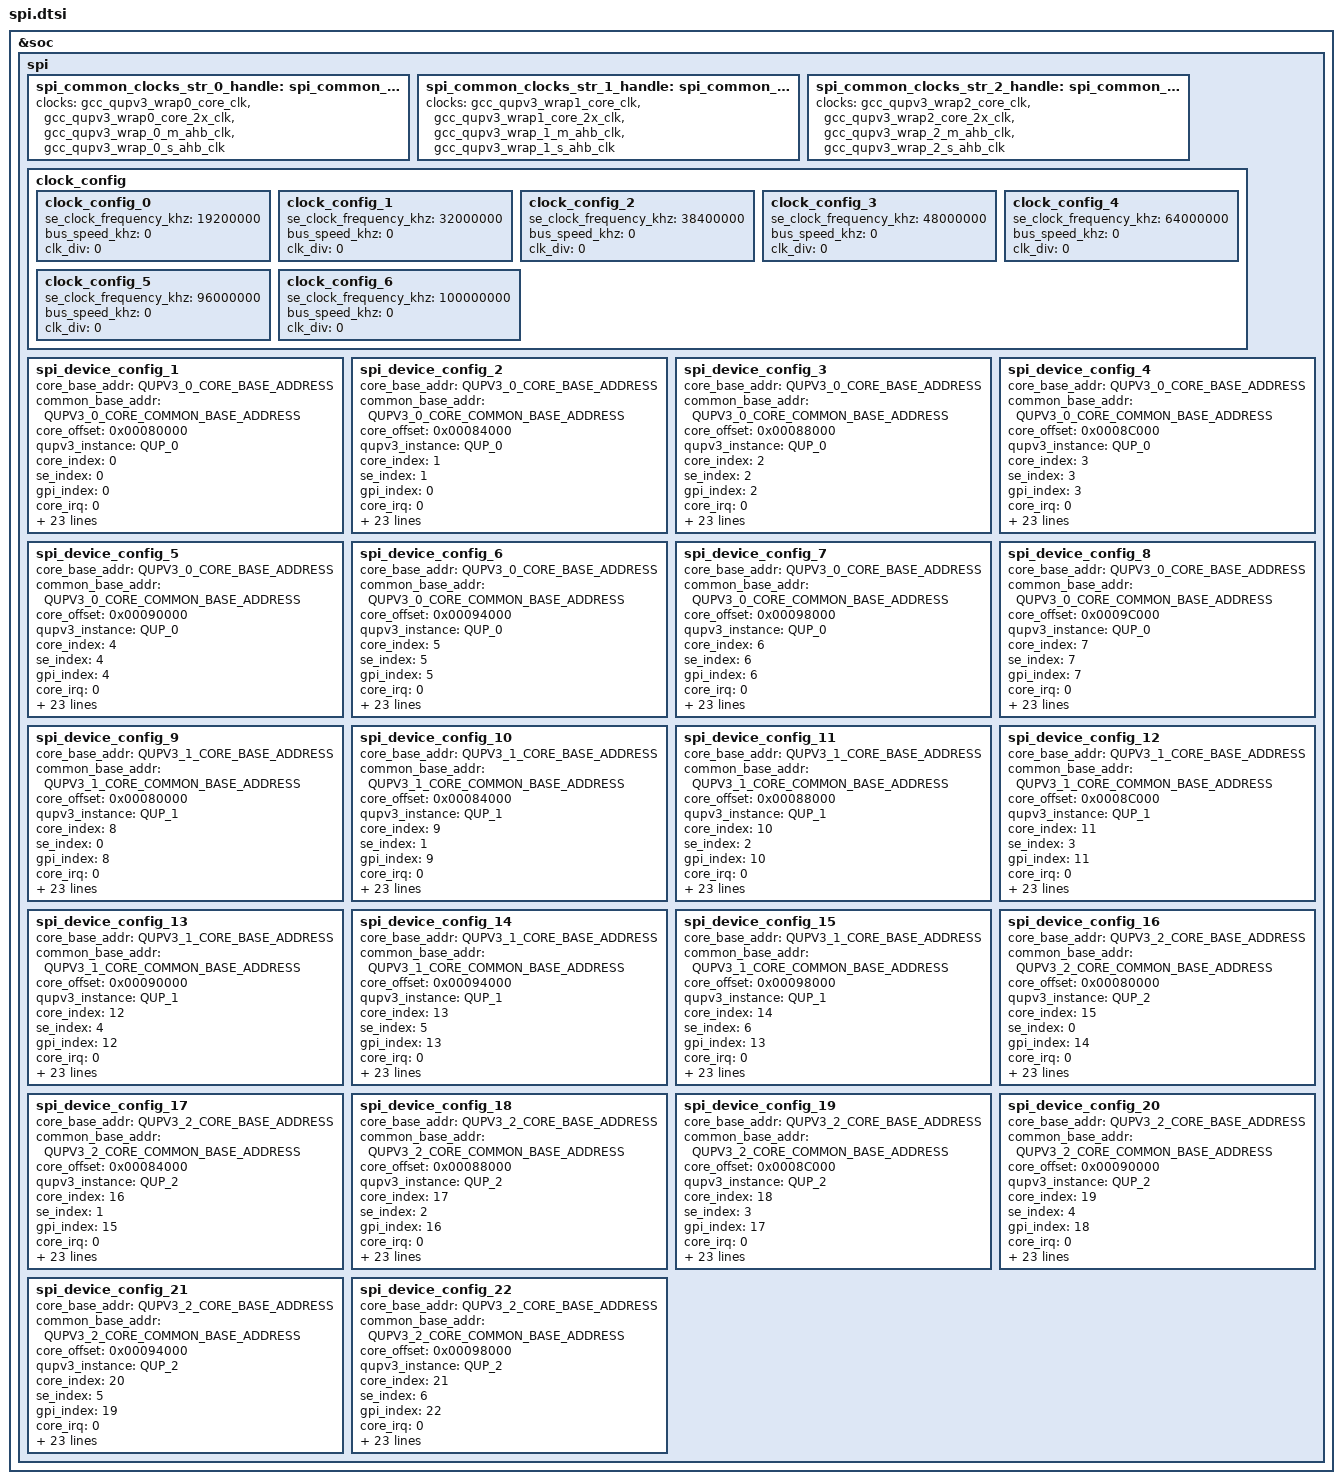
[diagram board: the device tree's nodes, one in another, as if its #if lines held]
/**

This is the settings file for spi

Copyright (c) 2021, 2023 Qualcomm Technologies, Inc.
All Rights Reserved.
Confidential and Proprietary - Qualcomm Technologies, Inc.
*/

#include <spi_defines.h>

&soc {
 spi {
  spi_common_clocks_str_0_handle:spi_common_clocks_str_0 {
    clocks = "gcc_qupv3_wrap0_core_clk", "gcc_qupv3_wrap0_core_2x_clk",
             "gcc_qupv3_wrap_0_m_ahb_clk", "gcc_qupv3_wrap_0_s_ahb_clk" ;
  };
  spi_common_clocks_str_1_handle:spi_common_clocks_str_1 {
    clocks = "gcc_qupv3_wrap1_core_clk", "gcc_qupv3_wrap1_core_2x_clk",
             "gcc_qupv3_wrap_1_m_ahb_clk", "gcc_qupv3_wrap_1_s_ahb_clk";
  };
  spi_common_clocks_str_2_handle:spi_common_clocks_str_2 {
    clocks = "gcc_qupv3_wrap2_core_clk", "gcc_qupv3_wrap2_core_2x_clk",
             "gcc_qupv3_wrap_2_m_ahb_clk", "gcc_qupv3_wrap_2_s_ahb_clk" ;
  };
  clock_config {
      clock_config_0 {
        se_clock_frequency_khz =<19200000>;
        bus_speed_khz = <0>;
        clk_div = /bits/ 8 <0>;
      };
      clock_config_1 {
          se_clock_frequency_khz =<32000000>;
          bus_speed_khz = <0>;
          clk_div = /bits/ 8 <0>;
      };
      clock_config_2 {
          se_clock_frequency_khz =<38400000>;
          bus_speed_khz = <0>;
          clk_div = /bits/ 8 <0>;
      };
      clock_config_3 {
          se_clock_frequency_khz =<48000000>;
          bus_speed_khz = <0>;
          clk_div = /bits/ 8 <0>;
      };
      clock_config_4 {
          se_clock_frequency_khz =<64000000>;
          bus_speed_khz = <0>;
          clk_div = /bits/ 8 <0>;
      };
      clock_config_5 {
          se_clock_frequency_khz =<96000000>;
          bus_speed_khz = <0>;
          clk_div = /bits/ 8 <0>;
      };
      clock_config_6 {
          se_clock_frequency_khz =<100000000>;
          bus_speed_khz = <0>;
          clk_div = /bits/ 8 <0>;
      };
    };
#ifdef SSC_USE_SPI_01
  spi_device_config_1 {
    core_base_addr              = <QUPV3_0_CORE_BASE_ADDRESS>;
    common_base_addr            = <QUPV3_0_CORE_COMMON_BASE_ADDRESS>;
    core_offset                 = <0x00080000>;
    qupv3_instance              = /bits/ 8 <QUP_0>;
    core_index                  = /bits/ 8 <0>;
    se_index                    = /bits/ 8 <0>;
    gpi_index                   = /bits/ 8 <0>;
    core_irq                    = <0>;
    polled_mode                 = <1>;
    min_data_length_for_dma     = <0>;
    
    miso_encoding                = <SPI_01_MISO>;
    mosi_encoding                = <SPI_01_MOSI>;
    clk_encoding                 = <SPI_01_CLK>;
    cs_encoding_0                = <SPI_01_CS_0>;
    cs_encoding_1                = <0>;
    cs_encoding_2                = <0>;
    cs_encoding_3                = <0>;
    sleep_miso_encoding          = <0>;
    sleep_mosi_encoding          = <0>;
    sleep_clk_encoding           = <0>;
    sleep_cs_encoding_0          = <0>;
	sleep_cs_encoding_1          = <0>;
	sleep_cs_encoding_2          = <0>;
	sleep_cs_encoding_3          = <0>;

    tcsr_reg_offset             = <0x00000000>;
    tcsr_base_addr              = <0x01FC0000>;
    tcsr_reg_value              = <0x00000000>;
    
    se_clock_frequency          = <19200>;
    se_clock_dfs_index          = /bits/ 8 <1>;

    common_clocks               = <&spi_common_clocks_str_0_handle>;
    se_clock                    = "gcc_qupv3_wrap0_s0_clk";
  };
#endif
#ifdef SSC_USE_SPI_02
  spi_device_config_2 {
    core_base_addr              = <QUPV3_0_CORE_BASE_ADDRESS>;
    common_base_addr            = <QUPV3_0_CORE_COMMON_BASE_ADDRESS>;
    core_offset                 = <0x00084000>;
    qupv3_instance              = /bits/ 8 <QUP_0>;
    core_index                  = /bits/ 8 <1>;
    se_index                    = /bits/ 8 <1>;
    gpi_index                   = /bits/ 8 <0>;
    core_irq                    = <0>;
    polled_mode                 = <1>;
    min_data_length_for_dma     = <0>;
    
    miso_encoding                = <SPI_02_MISO>;
    mosi_encoding                = <SPI_02_MOSI>;
    clk_encoding                 = <SPI_02_CLK>;
    cs_encoding_0                = <SPI_02_CS_0>;
	cs_encoding_1                = <0>;
    cs_encoding_2                = <0>;
    cs_encoding_3                = <0>;
    sleep_miso_encoding          = <0>;
    sleep_mosi_encoding          = <0>;
    sleep_clk_encoding           = <0>;
    sleep_cs_encoding_0          = <0>;
	sleep_cs_encoding_1          = <0>;
	sleep_cs_encoding_2          = <0>;
	sleep_cs_encoding_3          = <0>;

    tcsr_reg_offset             = <0x00000000>;
    tcsr_base_addr              = <0x01FC0000>;
    tcsr_reg_value              = <0x00000000>;
    
    se_clock_frequency          = <19200>;
    se_clock_dfs_index          = /bits/ 8 <1>;
    
    common_clocks               = <&spi_common_clocks_str_0_handle>;
    se_clock                    = "gcc_qupv3_wrap0_s1_clk";
  };
#endif
#ifdef SSC_USE_SPI_03
  spi_device_config_3 {
    core_base_addr              = <QUPV3_0_CORE_BASE_ADDRESS>;
    common_base_addr            = <QUPV3_0_CORE_COMMON_BASE_ADDRESS>;
    core_offset                 = <0x00088000>;
    qupv3_instance              = /bits/ 8 <QUP_0>;
    core_index                  = /bits/ 8 <2>;
    se_index                    = /bits/ 8 <2>;
    gpi_index                   = /bits/ 8 <2>;
    core_irq                    = <0>;
    polled_mode                 = <1>;
    min_data_length_for_dma     = <0>;
    
    
    miso_encoding                = <SPI_03_MISO>;
    mosi_encoding                = <SPI_03_MOSI>;
    clk_encoding                 = <SPI_03_CLK>;
    cs_encoding_0                = <SPI_03_CS_0>;
    cs_encoding_1                = <0>;
    cs_encoding_2                = <0>;
    cs_encoding_3                = <0>;
    sleep_miso_encoding          = <0>;
    sleep_mosi_encoding          = <0>;
    sleep_clk_encoding           = <0>;
    sleep_cs_encoding_0          = <0>;
	sleep_cs_encoding_1          = <0>;
	sleep_cs_encoding_2          = <0>;
	sleep_cs_encoding_3          = <0>;

    tcsr_reg_offset             = <0x00000000>;
    tcsr_base_addr              = <0x01FC0000>;    
    tcsr_reg_value              = <0x00000000>;
    
    se_clock_frequency          = <19200>;
    se_clock_dfs_index          = /bits/ 8 <1>;    

    common_clocks               = <&spi_common_clocks_str_0_handle>;
    se_clock                    = "gcc_qupv3_wrap0_s2_clk";

  };
#endif
#ifdef SSC_USE_SPI_04
  spi_device_config_4 {
    core_base_addr              = <QUPV3_0_CORE_BASE_ADDRESS>;
    common_base_addr            = <QUPV3_0_CORE_COMMON_BASE_ADDRESS>;
    core_offset                 = <0x0008C000>;
    qupv3_instance              = /bits/ 8 <QUP_0>;
    core_index                  = /bits/ 8 <3>;
    se_index                    = /bits/ 8 <3>;
    gpi_index                   = /bits/ 8 <3>;
    core_irq                    = <0>;
    polled_mode                 = <1>;
    min_data_length_for_dma     = <0>;
    
    
    miso_encoding                = <SPI_04_MISO>;
    mosi_encoding                = <SPI_04_MOSI>;
    clk_encoding                 = <SPI_04_CLK>;
    cs_encoding_0                = <SPI_04_CS_0>;
    cs_encoding_1                = <0>;
    cs_encoding_2                = <0>;
    cs_encoding_3                = <0>;
    sleep_miso_encoding          = <0>;
    sleep_mosi_encoding          = <0>;
    sleep_clk_encoding           = <0>;
    sleep_cs_encoding_0          = <0>;
	sleep_cs_encoding_1          = <0>;
	sleep_cs_encoding_2          = <0>;
	sleep_cs_encoding_3          = <0>;

    tcsr_reg_offset             = <0x00000000>;
    tcsr_base_addr              = <0x01FC0000>;    
    tcsr_reg_value              = <0x00000000>;
    
    se_clock_frequency          = <19200>;
    se_clock_dfs_index          = /bits/ 8 <1>;
    
    common_clocks               = <&spi_common_clocks_str_0_handle>;
    se_clock                    = "gcc_qupv3_wrap0_s3_clk";
  };
#endif
#ifdef SSC_USE_SPI_05
  spi_device_config_5 {
    core_base_addr              = <QUPV3_0_CORE_BASE_ADDRESS>;
    common_base_addr            = <QUPV3_0_CORE_COMMON_BASE_ADDRESS>;
    core_offset                 = <0x00090000>;
    qupv3_instance              = /bits/ 8 <QUP_0>;
    core_index                  = /bits/ 8 <4>;
    se_index                    = /bits/ 8 <4>;
    gpi_index                   = /bits/ 8 <4>;
    core_irq                    = <0>;
    polled_mode                 = <1>;
    min_data_length_for_dma     = <0>;
        
    miso_encoding                = <SPI_05_MISO>;
    mosi_encoding                = <SPI_05_MOSI>;
    clk_encoding                 = <SPI_05_CLK>;
    cs_encoding_0                = <SPI_05_CS_0>;
    cs_encoding_1                = <0>;
    cs_encoding_2                = <0>;
    cs_encoding_3                = <0>;
    sleep_miso_encoding          = <0>;
    sleep_mosi_encoding          = <0>;
    sleep_clk_encoding           = <0>;
    sleep_cs_encoding_0          = <0>;
	sleep_cs_encoding_1          = <0>;
	sleep_cs_encoding_2          = <0>;
	sleep_cs_encoding_3          = <0>;

    tcsr_reg_offset             = <0x00000000>;
    tcsr_base_addr              = <0x01FC0000>;    
    tcsr_reg_value              = <0x00000000>;
    
    se_clock_frequency          = <19200>;
    se_clock_dfs_index          = /bits/ 8 <1>;
    
    common_clocks               = <&spi_common_clocks_str_0_handle>;
    se_clock                    = "gcc_qupv3_wrap0_s4_clk";
	
  };
#endif
#ifdef SSC_USE_SPI_06
  spi_device_config_6 {
    core_base_addr              = <QUPV3_0_CORE_BASE_ADDRESS>;
    common_base_addr            = <QUPV3_0_CORE_COMMON_BASE_ADDRESS>;
    core_offset                 = <0x00094000>;
    qupv3_instance              = /bits/ 8 <QUP_0>;
    core_index                  = /bits/ 8 <5>;
    se_index                    = /bits/ 8 <5>;
    gpi_index                   = /bits/ 8 <5>;
    core_irq                    = <0>;
    polled_mode                 = <1>;
    min_data_length_for_dma     = <0>;
        
    miso_encoding               = <SPI_06_MISO>;
    mosi_encoding               = <SPI_06_MOSI>;
    clk_encoding                = <SPI_06_CLK>;
    cs_encoding_0               = <SPI_06_CS_0>;
    cs_encoding_1               = <0>;
    cs_encoding_2               = <0>;
    cs_encoding_3               = <0>;
    sleep_miso_encoding         = <0>;
    sleep_mosi_encoding         = <0>;
    sleep_clk_encoding          = <0>;
    sleep_cs_encoding_0         = <0>;
	sleep_cs_encoding_1         = <0>;
	sleep_cs_encoding_2         = <0>;
	sleep_cs_encoding_3         = <0>;

    tcsr_reg_offset             = <0x00000000>;
    tcsr_base_addr              = <0x01FC0000>;
    tcsr_reg_value              = <0x00000000>;
    
    se_clock_frequency          = <19200>;
    se_clock_dfs_index          = /bits/ 8 <1>;

    common_clocks               = <&spi_common_clocks_str_0_handle>;
    se_clock                    = "gcc_qupv3_wrap0_s5_clk";
	
  };
#endif
#ifdef SSC_USE_SPI_07
  spi_device_config_7 {
    core_base_addr              = <QUPV3_0_CORE_BASE_ADDRESS>;
    common_base_addr            = <QUPV3_0_CORE_COMMON_BASE_ADDRESS>;
    core_offset                 = <0x00098000>;
    qupv3_instance              = /bits/ 8 <QUP_0>;
    core_index                  = /bits/ 8 <6>;
    se_index                    = /bits/ 8 <6>;
    gpi_index                   = /bits/ 8 <6>;
    core_irq                    = <0>;
    polled_mode                 = <1>;
    min_data_length_for_dma     = <0>;
    
    
    miso_encoding               = <SPI_07_MISO>;
    mosi_encoding               = <SPI_07_MOSI>;
    clk_encoding                = <SPI_07_CLK>;
    cs_encoding_0               = <SPI_07_CS_0>;
    cs_encoding_1               = <0>;
    cs_encoding_2               = <0>;
    cs_encoding_3               = <0>;
    sleep_miso_encoding         = <0>;
    sleep_mosi_encoding         = <0>;
    sleep_clk_encoding          = <0>;
    sleep_cs_encoding_0         = <0>;
	sleep_cs_encoding_1         = <0>;
	sleep_cs_encoding_2         = <0>;
	sleep_cs_encoding_3         = <0>;

    tcsr_reg_offset             = <0x00000000>;
    tcsr_base_addr              = <0x01FC0000>;
    tcsr_reg_value              = <0x00000000>;
    
    se_clock_frequency          = <19200>;
    se_clock_dfs_index          = /bits/ 8 <1>;
    
    common_clocks               = <&spi_common_clocks_str_0_handle>;
    se_clock                    = "gcc_qupv3_wrap0_s6_clk";
	
  };
#endif
#ifdef SSC_USE_SPI_08
  spi_device_config_8 {
    core_base_addr              = <QUPV3_0_CORE_BASE_ADDRESS>;
    common_base_addr            = <QUPV3_0_CORE_COMMON_BASE_ADDRESS>;
    core_offset                 = <0x0009C000>;
    qupv3_instance              = /bits/ 8 <QUP_0>;
    core_index                  = /bits/ 8 <7>;
    se_index                    = /bits/ 8 <7>;
    gpi_index                   = /bits/ 8 <7>;
    core_irq                    = <0>;
    polled_mode                 = <1>;
    min_data_length_for_dma     = <0>;
    
    miso_encoding               = <SPI_08_MISO>;
    mosi_encoding               = <SPI_08_MOSI>;
    clk_encoding                = <SPI_08_CLK>;
    cs_encoding_0               = <SPI_08_CS_0>;
    cs_encoding_1               = <0>;
    cs_encoding_2               = <0>;
    cs_encoding_3               = <0>;
    sleep_miso_encoding         = <0>;
    sleep_mosi_encoding         = <0>;
    sleep_clk_encoding          = <0>;
    sleep_cs_encoding_0         = <0>;
	sleep_cs_encoding_1         = <0>;
	sleep_cs_encoding_2         = <0>;
	sleep_cs_encoding_3         = <0>;

    tcsr_reg_offset             = <0x00000000>;
    tcsr_base_addr              = <0x01FC0000>;
    tcsr_reg_value              = <0x00000000>;
    
    se_clock_frequency          = <19200>;
    se_clock_dfs_index          = /bits/ 8 <1>;    

    common_clocks               = <&spi_common_clocks_str_0_handle>;
    se_clock                    = "gcc_qupv3_wrap0_s7_clk";
  };
#endif
#ifdef SSC_USE_SPI_09
  spi_device_config_9 {
    core_base_addr              = <QUPV3_1_CORE_BASE_ADDRESS>;
    common_base_addr            = <QUPV3_1_CORE_COMMON_BASE_ADDRESS>;
    core_offset                 = <0x00080000>;
    qupv3_instance              = /bits/ 8 <QUP_1>;
    core_index                  = /bits/ 8 <8>;
    se_index                    = /bits/ 8 <0>;
    gpi_index                   = /bits/ 8 <8>;
    core_irq                    = <0>;
    polled_mode                 = <1>;
    min_data_length_for_dma     = <0>;
    
    miso_encoding               = <SPI_09_MISO>;
    mosi_encoding               = <SPI_09_MOSI>;
    clk_encoding                = <SPI_09_CLK>;
    cs_encoding_0               = <SPI_09_CS_0>;
    cs_encoding_1               = <0>;
    cs_encoding_2               = <0>;
    cs_encoding_3               = <0>;
    sleep_miso_encoding         = <0>;
    sleep_mosi_encoding         = <0>;
    sleep_clk_encoding          = <0>;
    sleep_cs_encoding_0         = <0>;
	sleep_cs_encoding_1         = <0>;
	sleep_cs_encoding_2         = <0>;
	sleep_cs_encoding_3         = <0>;

    tcsr_reg_offset             = <0x00000000>;
    tcsr_base_addr              = <0x01FC0000>;
    tcsr_reg_value              = <0x00000000>;

    se_clock_frequency          = <19200>;
    se_clock_dfs_index          = /bits/ 8 <1>;    
    
    common_clocks               = <&spi_common_clocks_str_1_handle>;
    se_clock                    = "gcc_qupv3_wrap1_s0_clk";
	
  };
#endif
#ifdef SSC_USE_SPI_10
  spi_device_config_10 {
    core_base_addr              = <QUPV3_1_CORE_BASE_ADDRESS>;
    common_base_addr            = <QUPV3_1_CORE_COMMON_BASE_ADDRESS>;
    core_offset                 = <0x00084000>;
    qupv3_instance              = /bits/ 8 <QUP_1>;
    core_index                  = /bits/ 8 <9>;
    se_index                    = /bits/ 8 <1>;
    gpi_index                   = /bits/ 8 <9>;
    core_irq                    = <0>;
    polled_mode                 = <1>;
    min_data_length_for_dma     = <0>;
        
    miso_encoding               = <SPI_10_MISO>;
    mosi_encoding               = <SPI_10_MOSI>;
    clk_encoding                = <SPI_10_CLK>;
    cs_encoding_0               = <SPI_10_CS_0>;
    cs_encoding_1               = <0>;
    cs_encoding_2               = <0>;
    cs_encoding_3               = <0>;
    sleep_miso_encoding         = <0>;
    sleep_mosi_encoding         = <0>;
    sleep_clk_encoding          = <0>;
    sleep_cs_encoding_0         = <0>;
	sleep_cs_encoding_1         = <0>;
	sleep_cs_encoding_2         = <0>;
	sleep_cs_encoding_3         = <0>;

    tcsr_reg_offset             = <0x00000000>;
    tcsr_base_addr              = <0x01FC0000>;
    tcsr_reg_value              = <0x00000000>;
    
    se_clock_frequency          = <19200>;
    se_clock_dfs_index          = /bits/ 8 <1>;

    common_clocks               = <&spi_common_clocks_str_1_handle>;
    se_clock                    = "gcc_qupv3_wrap1_s1_clk";

  };
#endif
#ifdef SSC_USE_SPI_11
  spi_device_config_11 {
    core_base_addr              = <QUPV3_1_CORE_BASE_ADDRESS>;
    common_base_addr            = <QUPV3_1_CORE_COMMON_BASE_ADDRESS>;
    core_offset                 = <0x00088000>;
    qupv3_instance              = /bits/ 8 <QUP_1>;
    core_index                  = /bits/ 8 <10>;
    se_index                    = /bits/ 8 <2>;
    gpi_index                   = /bits/ 8 <10>;
    core_irq                    = <0>;
    polled_mode                 = <1>;
    min_data_length_for_dma     = <0>;
    
    miso_encoding               = <SPI_11_MISO>;
    mosi_encoding               = <SPI_11_MOSI>;
    clk_encoding                = <SPI_11_CLK>;
    cs_encoding_0               = <SPI_11_CS_0>;
    cs_encoding_1               = <0>;
    cs_encoding_2               = <0>;
    cs_encoding_3               = <0>;
    sleep_miso_encoding         = <0>;
    sleep_mosi_encoding         = <0>;
    sleep_clk_encoding          = <0>;
    sleep_cs_encoding_0         = <0>;
	sleep_cs_encoding_1         = <0>;
	sleep_cs_encoding_2         = <0>;
	sleep_cs_encoding_3         = <0>;

    tcsr_reg_offset             = <0x00000000>;
    tcsr_base_addr              = <0x01FC0000>;
    tcsr_reg_value              = <0x00000000>;
    
    se_clock_frequency          = <19200>;
    se_clock_dfs_index          = /bits/ 8 <1>;    

    common_clocks               = <&spi_common_clocks_str_1_handle>;
    se_clock                    = "gcc_qupv3_wrap1_s2_clk";

  };
#endif
#ifdef SSC_USE_SPI_12
  spi_device_config_12 {
    core_base_addr              = <QUPV3_1_CORE_BASE_ADDRESS>;
    common_base_addr            = <QUPV3_1_CORE_COMMON_BASE_ADDRESS>;
    core_offset                 = <0x0008C000>;
    qupv3_instance              = /bits/ 8 <QUP_1>;
    core_index                  = /bits/ 8 <11>;
    se_index                    = /bits/ 8 <3>;
    gpi_index                   = /bits/ 8 <11>;
    core_irq                    = <0>;
    polled_mode                 = <1>;
    min_data_length_for_dma     = <0>;
    
    miso_encoding               = <SPI_12_MISO>;
    mosi_encoding               = <SPI_12_MOSI>;
    clk_encoding                = <SPI_12_CLK>;
    cs_encoding_0               = <SPI_12_CS_0>;
    cs_encoding_1               = <0>;
    cs_encoding_2               = <0>;
    cs_encoding_3               = <0>;
    sleep_miso_encoding         = <0>;
    sleep_mosi_encoding         = <0>;
    sleep_clk_encoding          = <0>;
    sleep_cs_encoding_0         = <0>;
	sleep_cs_encoding_1         = <0>;
	sleep_cs_encoding_2         = <0>;
	sleep_cs_encoding_3         = <0>;

    tcsr_reg_offset             = <0x00000000>;
    tcsr_base_addr              = <0x01FC0000>;
    tcsr_reg_value              = <0x00000000>;

    se_clock_frequency          = <19200>;
    se_clock_dfs_index          = /bits/ 8 <1>;
    
    common_clocks               = <&spi_common_clocks_str_1_handle>;
    se_clock                    = "gcc_qupv3_wrap1_s3_clk";
  };
#endif
#ifdef SSC_USE_SPI_13
  spi_device_config_13 {
    core_base_addr              = <QUPV3_1_CORE_BASE_ADDRESS>;
    common_base_addr            = <QUPV3_1_CORE_COMMON_BASE_ADDRESS>;
    core_offset                 = <0x00090000>;
    qupv3_instance              = /bits/ 8 <QUP_1>;
    core_index                  = /bits/ 8 <12>;
    se_index                    = /bits/ 8 <4>;
    gpi_index                   = /bits/ 8 <12>;
    core_irq                    = <0>;
    polled_mode                 = <1>;
    min_data_length_for_dma     = <0>;
    
    miso_encoding               = <SPI_13_MISO>;
    mosi_encoding               = <SPI_13_MOSI>;
    clk_encoding                = <SPI_13_CLK>;
    cs_encoding_0               = <SPI_13_CS_0>;
    cs_encoding_1               = <0>;
    cs_encoding_2               = <0>;
    cs_encoding_3               = <0>;
    sleep_miso_encoding         = <0>;
    sleep_mosi_encoding         = <0>;
    sleep_clk_encoding          = <0>;
    sleep_cs_encoding_0         = <0>;
	sleep_cs_encoding_1         = <0>;
	sleep_cs_encoding_2         = <0>;
	sleep_cs_encoding_3         = <0>;

    tcsr_reg_offset             = <0x00000000>;
    tcsr_base_addr              = <0x01FC0000>;
    tcsr_reg_value              = <0x00000000>;
    
    se_clock_frequency          = <19200>;
    se_clock_dfs_index          = /bits/ 8 <1>;
    
    common_clocks               = <&spi_common_clocks_str_1_handle>;
    se_clock                    = "gcc_qupv3_wrap1_s4_clk";
  };
#endif
#ifdef SSC_USE_SPI_14
  spi_device_config_14 {
    core_base_addr              = <QUPV3_1_CORE_BASE_ADDRESS>;
    common_base_addr            = <QUPV3_1_CORE_COMMON_BASE_ADDRESS>;
    core_offset                 = <0x00094000>;
    qupv3_instance              = /bits/ 8 <QUP_1>;
    core_index                  = /bits/ 8 <13>;
    se_index                    = /bits/ 8 <5>;
    gpi_index                   = /bits/ 8 <13>;
    core_irq                    = <0>;
    polled_mode                 = <1>;
    min_data_length_for_dma     = <0>;
    
    
    miso_encoding               = <SPI_14_MISO>;
    mosi_encoding               = <SPI_14_MOSI>;
    clk_encoding                = <SPI_14_CLK>;
    cs_encoding_0               = <SPI_14_CS_0>;
    cs_encoding_1               = <0>;
    cs_encoding_2               = <0>;
    cs_encoding_3               = <0>;
    sleep_miso_encoding         = <0>;
    sleep_mosi_encoding         = <0>;
    sleep_clk_encoding          = <0>;
    sleep_cs_encoding_0         = <0>;
	sleep_cs_encoding_1         = <0>;
	sleep_cs_encoding_2         = <0>;
	sleep_cs_encoding_3         = <0>;

    tcsr_reg_offset             = <0x00000000>;
    tcsr_base_addr              = <0x01FC0000>;
    tcsr_reg_value              = <0x00000000>;
    
    se_clock_frequency          = <19200>;
    se_clock_dfs_index          = /bits/ 8 <1>;

    common_clocks               = <&spi_common_clocks_str_1_handle>;
    se_clock                    = "gcc_qupv3_wrap1_s5_clk";
  };
#endif
#ifdef SSC_USE_SPI_15
  spi_device_config_15 {
    core_base_addr              = <QUPV3_1_CORE_BASE_ADDRESS>;
    common_base_addr            = <QUPV3_1_CORE_COMMON_BASE_ADDRESS>;
    core_offset                 = <0x00098000>;
    qupv3_instance              = /bits/ 8 <QUP_1>;
    core_index                  = /bits/ 8 <14>;
    se_index                    = /bits/ 8 <6>;
    gpi_index                   = /bits/ 8 <13>;
    core_irq                    = <0>;
    polled_mode                 = <1>;
    min_data_length_for_dma     = <0>;
    
    miso_encoding               = <SPI_15_MISO>;
    mosi_encoding               = <SPI_15_MOSI>;
    clk_encoding                = <SPI_15_CLK>;
    cs_encoding_0               = <SPI_15_CS_0>;
    cs_encoding_1               = <0>;
    cs_encoding_2               = <0>;
    cs_encoding_3               = <0>;
    sleep_miso_encoding         = <0>;
    sleep_mosi_encoding         = <0>;
    sleep_clk_encoding          = <0>;
    sleep_cs_encoding_0         = <0>;
	sleep_cs_encoding_1         = <0>;
	sleep_cs_encoding_2         = <0>;
	sleep_cs_encoding_3         = <0>;

    tcsr_reg_offset             = <0x00000000>;
    tcsr_base_addr              = <0x01FC0000>;
    tcsr_reg_value              = <0x00000000>;
    
    se_clock_frequency          = <19200>;
    se_clock_dfs_index          = /bits/ 8 <1>;
    
    common_clocks               = <&spi_common_clocks_str_1_handle>;
    se_clock                    = "gcc_qupv3_wrap1_s6_clk";

  };
#endif
#ifdef SSC_USE_SPI_16
  spi_device_config_16 {
    core_base_addr              = <QUPV3_2_CORE_BASE_ADDRESS>;
    common_base_addr            = <QUPV3_2_CORE_COMMON_BASE_ADDRESS>;
    core_offset                 = <0x00080000>;
    qupv3_instance              = /bits/ 8 <QUP_2>;
    core_index                  = /bits/ 8 <15>;
    se_index                    = /bits/ 8 <0>;
    gpi_index                   = /bits/ 8 <14>;
    core_irq                    = <0>;
    polled_mode                 = <1>;
    min_data_length_for_dma     = <0>;
    
    miso_encoding               = <SPI_16_MISO>;
    mosi_encoding               = <SPI_16_MOSI>;
    clk_encoding                = <SPI_16_CLK>;
    cs_encoding_0               = <SPI_16_CS_0>;
    cs_encoding_1               = <0>;
    cs_encoding_2               = <0>;
    cs_encoding_3               = <0>;
    sleep_miso_encoding         = <0>;
    sleep_mosi_encoding         = <0>;
    sleep_clk_encoding          = <0>;
    sleep_cs_encoding_0         = <0>;
	sleep_cs_encoding_1         = <0>;
	sleep_cs_encoding_2         = <0>;
	sleep_cs_encoding_3         = <0>;

    tcsr_reg_offset             = <0x00000000>;
    tcsr_base_addr              = <0x01FC0000>;
    tcsr_reg_value              = <0x00000000>;
    
    se_clock_frequency          = <19200>;
    se_clock_dfs_index          = /bits/ 8 <1>;
    
    common_clocks               =  <&spi_common_clocks_str_2_handle> ;
    se_clock                    = "gcc_qupv3_wrap2_s0_clk";
  };
#endif
#ifdef SSC_USE_SPI_17
  spi_device_config_17 {
    core_base_addr              = <QUPV3_2_CORE_BASE_ADDRESS>;
    common_base_addr            = <QUPV3_2_CORE_COMMON_BASE_ADDRESS>;
    core_offset                 = <0x00084000>;
    qupv3_instance              = /bits/ 8 <QUP_2>;
    core_index                  = /bits/ 8 <16>;
    se_index                    = /bits/ 8 <1>;
    gpi_index                   = /bits/ 8 <15>;
    core_irq                    = <0>;
    polled_mode                 = <1>;
    min_data_length_for_dma     = <0>;
    
    miso_encoding               = <SPI_17_MISO>;
    mosi_encoding               = <SPI_17_MOSI>;
    clk_encoding                = <SPI_17_CLK>;
    cs_encoding_0               = <SPI_17_CS_0>;
    cs_encoding_1               = <0>;
    cs_encoding_2               = <0>;
    cs_encoding_3               = <0>;
    sleep_miso_encoding         = <0>;
    sleep_mosi_encoding         = <0>;
    sleep_clk_encoding          = <0>;
    sleep_cs_encoding_0         = <0>;
	sleep_cs_encoding_1         = <0>;
	sleep_cs_encoding_2         = <0>;
	sleep_cs_encoding_3         = <0>;

    tcsr_reg_offset             = <0x00000000>;
    tcsr_base_addr              = <0x01FC0000>;
    tcsr_reg_value              = <0x00000000>;
    
    se_clock_frequency          = <19200>;
    se_clock_dfs_index          = /bits/ 8 <1>;
    
    common_clocks               =  <&spi_common_clocks_str_2_handle> ;
    se_clock                    = "gcc_qupv3_wrap2_s1_clk";
  };
#endif
#ifdef SSC_USE_SPI_18
  spi_device_config_18 {
    core_base_addr              = <QUPV3_2_CORE_BASE_ADDRESS>;
    common_base_addr            = <QUPV3_2_CORE_COMMON_BASE_ADDRESS>;
    core_offset                 = <0x00088000>;
    qupv3_instance              = /bits/ 8 <QUP_2>;
    core_index                  = /bits/ 8 <17>;
    se_index                    = /bits/ 8 <2>;
    gpi_index                   = /bits/ 8 <16>;
    core_irq                    = <0>;
    polled_mode                 = <1>;
    min_data_length_for_dma     = <0>;
    
    miso_encoding               = <SPI_18_MISO>;
    mosi_encoding               = <SPI_18_MOSI>;
    clk_encoding                = <SPI_18_CLK>;
    cs_encoding_0               = <SPI_18_CS_0>;
    cs_encoding_1               = <0>;
    cs_encoding_2               = <0>;
    cs_encoding_3               = <0>;
    sleep_miso_encoding         = <0>;
    sleep_mosi_encoding         = <0>;
    sleep_clk_encoding          = <0>;
    sleep_cs_encoding_0         = <0>;
	sleep_cs_encoding_1         = <0>;
	sleep_cs_encoding_2         = <0>;
	sleep_cs_encoding_3         = <0>;

    tcsr_reg_offset             = <0x00000000>;
    tcsr_base_addr              = <0x01FC0000>;
    tcsr_reg_value              = <0x00000000>;
    
    se_clock_frequency          = <19200>;
    se_clock_dfs_index          = /bits/ 8 <1>;
    
    common_clocks               =  <&spi_common_clocks_str_2_handle> ;
    se_clock                    = "gcc_qupv3_wrap2_s2_clk";

  };
#endif
#ifdef SSC_USE_SPI_19
  spi_device_config_19 {
    core_base_addr              = <QUPV3_2_CORE_BASE_ADDRESS>;
    common_base_addr            = <QUPV3_2_CORE_COMMON_BASE_ADDRESS>;
    core_offset                 = <0x0008C000>;
    qupv3_instance              = /bits/ 8 <QUP_2>;
    core_index                  = /bits/ 8 <18>;
    se_index                    = /bits/ 8 <3>;
    gpi_index                   = /bits/ 8 <17>;
    core_irq                    = <0>;
    polled_mode                 = <1>;
    min_data_length_for_dma     = <0>;
    
    miso_encoding               = <SPI_19_MISO>;
    mosi_encoding               = <SPI_19_MOSI>;
    clk_encoding                = <SPI_19_CLK>;
    cs_encoding_0               = <SPI_19_CS_0>;
    cs_encoding_1               = <0>;
    cs_encoding_2               = <0>;
    cs_encoding_3               = <0>;
    sleep_miso_encoding         = <0>;
    sleep_mosi_encoding         = <0>;
    sleep_clk_encoding          = <0>;
    sleep_cs_encoding_0         = <0>;
	sleep_cs_encoding_1         = <0>;
	sleep_cs_encoding_2         = <0>;
	sleep_cs_encoding_3         = <0>;

    tcsr_reg_offset             = <0x00000000>;
    tcsr_base_addr              = <0x01FC0000>;
    tcsr_reg_value              = <0x00000000>;
    
    se_clock_frequency          = <19200>;
    se_clock_dfs_index          = /bits/ 8 <1>;    

    common_clocks               =  <&spi_common_clocks_str_2_handle> ;
    se_clock                    = "gcc_qupv3_wrap2_s3_clk";
  };
#endif
#ifdef SSC_USE_SPI_20
  spi_device_config_20 {
    core_base_addr              = <QUPV3_2_CORE_BASE_ADDRESS>;
    common_base_addr            = <QUPV3_2_CORE_COMMON_BASE_ADDRESS>;
    core_offset                 = <0x00090000>;
    qupv3_instance              = /bits/ 8 <QUP_2>;
    core_index                  = /bits/ 8 <19>;
    se_index                    = /bits/ 8 <4>;
    gpi_index                   = /bits/ 8 <18>;
    core_irq                    = <0>;
    polled_mode                 = <1>;
    min_data_length_for_dma     = <0>;
    
    miso_encoding               = <SPI_20_MISO>;
    mosi_encoding               = <SPI_20_MOSI>;
    clk_encoding                = <SPI_20_CLK>;
    cs_encoding_0               = <SPI_20_CS_0>;
    cs_encoding_1               = <0>;
    cs_encoding_2               = <0>;
    cs_encoding_3               = <0>;
    sleep_miso_encoding         = <0>;
    sleep_mosi_encoding         = <0>;
    sleep_clk_encoding          = <0>;
    sleep_cs_encoding_0         = <0>;
	sleep_cs_encoding_1         = <0>;
	sleep_cs_encoding_2         = <0>;
	sleep_cs_encoding_3         = <0>;

    tcsr_reg_offset             = <0x00000000>;
    tcsr_base_addr              = <0x01FC0000>;
    tcsr_reg_value              = <0x00000000>;
    
    se_clock_frequency          = <19200>;
    se_clock_dfs_index          = /bits/ 8 <1>;
    
    common_clocks               =  <&spi_common_clocks_str_2_handle> ;
    se_clock                    = "gcc_qupv3_wrap2_s4_clk";
  };
#endif
#ifdef SSC_USE_SPI_21
  spi_device_config_21 {
    core_base_addr              = <QUPV3_2_CORE_BASE_ADDRESS>;
    common_base_addr            = <QUPV3_2_CORE_COMMON_BASE_ADDRESS>;
    core_offset                 = <0x00094000>;
    qupv3_instance              = /bits/ 8 <QUP_2>;
    core_index                  = /bits/ 8 <20>;
    se_index                    = /bits/ 8 <5>;
    gpi_index                   = /bits/ 8 <19>;
    core_irq                    = <0>;
    polled_mode                 = <1>;
    min_data_length_for_dma     = <0>;
    
    miso_encoding               = <SPI_21_MISO>;
    mosi_encoding               = <SPI_21_MOSI>;
    clk_encoding                = <SPI_21_CLK>;
    cs_encoding_0               = <SPI_21_CS_0>;
    cs_encoding_1               = <0>;
    cs_encoding_2               = <0>;
    cs_encoding_3               = <0>;
    sleep_miso_encoding         = <0>;
    sleep_mosi_encoding         = <0>;
    sleep_clk_encoding          = <0>;
    sleep_cs_encoding_0         = <0>;
	sleep_cs_encoding_1         = <0>;
	sleep_cs_encoding_2         = <0>;
	sleep_cs_encoding_3         = <0>;

    tcsr_reg_offset             = <0x00000000>;
    tcsr_base_addr              = <0x01FC0000>;
    tcsr_reg_value              = <0x00000000>;
    
    se_clock_frequency          = <19200>;
    se_clock_dfs_index          = /bits/ 8 <1>;
    
    common_clocks               =  <&spi_common_clocks_str_2_handle> ;
    se_clock                    = "gcc_qupv3_wrap2_s5_clk";
  };
#endif
#ifdef SSC_USE_SPI_22
  spi_device_config_22 {
    core_base_addr              = <QUPV3_2_CORE_BASE_ADDRESS>;
    common_base_addr            = <QUPV3_2_CORE_COMMON_BASE_ADDRESS>;
    core_offset                 = <0x00098000>;
    qupv3_instance              = /bits/ 8 <QUP_2>;
    core_index                  = /bits/ 8 <21>;
    se_index                    = /bits/ 8 <6>;
    gpi_index                   = /bits/ 8 <22>;
    core_irq                    = <0>;
    polled_mode                 = <1>;
    min_data_length_for_dma     = <0>;
    
    miso_encoding               = <SPI_22_MISO>;
    mosi_encoding               = <SPI_22_MOSI>;
    clk_encoding                = <SPI_22_CLK>;
    cs_encoding_0               = <SPI_22_CS_0>;
    cs_encoding_1               = <0>;
    cs_encoding_2               = <0>;
    cs_encoding_3               = <0>;
    sleep_miso_encoding         = <0>;
    sleep_mosi_encoding         = <0>;
    sleep_clk_encoding          = <0>;
    sleep_cs_encoding_0         = <0>;
	sleep_cs_encoding_1         = <0>;
	sleep_cs_encoding_2         = <0>;
	sleep_cs_encoding_3         = <0>;

    tcsr_reg_offset             = <0x00000000>;
    tcsr_base_addr              = <0x01FC0000>;
    tcsr_reg_value              = <0x00000000>;
    
    se_clock_frequency          = <19200>;
    se_clock_dfs_index          = /bits/ 8 <1>;    

    common_clocks               =  <&spi_common_clocks_str_2_handle> ;
    se_clock                    = "gcc_qupv3_wrap2_s6_clk";
  };
#endif
 };
};
